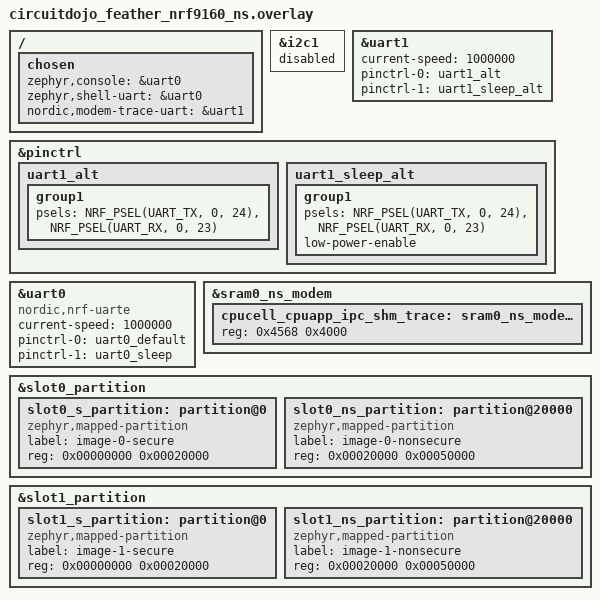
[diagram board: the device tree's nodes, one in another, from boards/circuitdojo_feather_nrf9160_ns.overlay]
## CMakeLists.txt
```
cmake_minimum_required(VERSION 3.20.0)

# Either authentication mode is selectable at build time.
set(SAMPLE_TLS verify psk)
include(${CMAKE_CURRENT_SOURCE_DIR}/../common/app.cmake)

find_package(Zephyr REQUIRED HINTS $ENV{ZEPHYR_BASE})
project(mqtt_init)

# The broker's trust anchor, included by main.c as a string literal on a
# certificate build. A broker with its own development CA is pointed at that
# file instead: -DPIGEON_MQTT_CA_FILE=<pem>.
set(PIGEON_MQTT_CA_FILE ${CMAKE_CURRENT_SOURCE_DIR}/cert/isrg-root-x2.pem
    CACHE FILEPATH "PEM trust anchor for the MQTT broker's certificate")

generate_inc_file_for_target(
  app ${PIGEON_MQTT_CA_FILE}
  ${ZEPHYR_BINARY_DIR}/include/generated/broker-ca.pem.hex
)

target_sources(app PRIVATE src/main.c src/shadow.c)

include(${CMAKE_CURRENT_SOURCE_DIR}/../common/net.cmake)
```

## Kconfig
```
config MQTT_INIT_PIGEON_ID
  string "Pigeon id this device connects to the broker as"
  default ""
  help
    The pigeon's own 64-character hex id, passed to pigeon_init() as
    pigeon_config.device_id. On this connector it is the CONNECT client id
    and username, and on a PSK build the handshake identity as well; the
    broker refuses a session whose three copies of it disagree. It is
    credential-shaped, so it belongs in the git-ignored prj.local.conf.

    The empty default fails at pigeon_mqtt_start() rather than connecting
    as nobody.

menu "Zephyr Kernel"
source "Kconfig.zephyr"
endmenu
```

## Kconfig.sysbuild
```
rsource "../Kconfig.sysbuild.signing"

# A Feather has nothing at address 0 without MCUboot. The ESP32-C6 board
# defaults to MCUboot, and this sample stages no firmware, so one image is
# enough there.
choice BOOTLOADER
	default BOOTLOADER_NONE if BOARD_ESP32C6_DEVKITC
	default BOOTLOADER_MCUBOOT if SOC_SERIES_NRF91
endchoice

source "share/sysbuild/Kconfig"
```

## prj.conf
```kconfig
# The Pigeon client library over MQTT: one persistent TLS session to the
# platform's broker, which bridges every publish onto the device routes. The
# endpoint names the broker rather than this pigeon (mqtts://<host>:8883, no
# path), and the pigeon id, token and PSK secret are device identity, so all
# of them belong in the git-ignored prj.local.conf.
CONFIG_PIGEON=y
CONFIG_PIGEON_CONNECTOR_MQTT=y
# The modem's credential store outlives a reflash and is keyed by tag, so each
# sample here owns a distinct one rather than the shared default.
CONFIG_PIGEON_MQTT_SEC_TAG=47

# Mains-powered and always on, so a minute of silence before the broker starts
# wondering is the right trade. A device that sleeps between reports wants
# this raised; the broker honours up to 30 minutes and closes after 1.5x.
CONFIG_MQTT_KEEPALIVE=60


CONFIG_LOG=y
CONFIG_LOG_DEFAULT_LEVEL=3
# Deferred, not immediate, because the log upload backend fills a ring buffer
# that is lock-free only while a single thread writes it. Deferred mode makes
# the log processing thread that sole writer.
CONFIG_LOG_MODE_DEFERRED=y
CONFIG_LOG_PROCESS_THREAD_STACK_SIZE=2048
# Lets the shadow's "log" field silence and restore logging at runtime.
CONFIG_LOG_RUNTIME_FILTERING=y

# This device's own logs, uploaded as Zephyr dictionary-encoded binary. The
# console stays human-readable; only the upload backend encodes. Decoding a
# chunk needs this build's log_dictionary.json, and a dictionary from another
# build decodes to plausible nonsense rather than erroring.
CONFIG_PIGEON_LOG_UPLOAD=y
CONFIG_PIGEON_LOG_UPLOAD_BUF_SIZE=4096
CONFIG_PIGEON_LOG_UPLOAD_BATCH_SIZE=2048

CONFIG_HEAP_MEM_POOL_SIZE=8192
CONFIG_MAIN_STACK_SIZE=8192
CONFIG_SYSTEM_WORKQUEUE_STACK_SIZE=4096
# Logging from the connection manager's event callbacks overflows the default.
CONFIG_NET_MGMT_EVENT_STACK_SIZE=2048

CONFIG_NETWORKING=y
CONFIG_NET_SOCKETS=y
CONFIG_NET_SOCKETS_SOCKOPT_TLS=y
# MQTT is a stream protocol, so this needs real TCP and at least one packet
# protocol under it, or the net stack refuses to build.
CONFIG_NET_TCP=y
CONFIG_NET_IPV4=y
CONFIG_NET_IPV6=y
CONFIG_NET_CONNECTION_MANAGER=y
CONFIG_NET_CONNECTION_MANAGER_MONITOR_STACK_SIZE=1024

# Generous rather than needed. The socket layer consults this only when the
# handshake has to block, so a cap that is exceeded abandons a session the
# broker has already accepted and surfaces as a bare timeout with no TLS
# error, which reads as a broken broker rather than a slow device.
CONFIG_NET_SOCKETS_TLS_CONNECT_TIMEOUT=45000
```

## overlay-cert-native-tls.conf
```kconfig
# Certificate mode on a board whose board conf selects TLS-PSK.
#
# Both want lists are compiled in on the mbedTLS boards, so this only picks
# which one the session uses.
CONFIG_PIGEON_MQTT_AUTH_CERT=y
```

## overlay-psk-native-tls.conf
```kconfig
# TLS-PSK on a board whose board conf selects certificate mode.
#
# Both want lists are compiled in on the mbedTLS boards, so this only picks
# which one the session uses.
CONFIG_PIGEON_MQTT_AUTH_PSK=y
# The broker's third PSK suite is AES-128-CBC; the shared fragment covers the
# other two.
CONFIG_PSA_WANT_ALG_CBC_NO_PADDING=y
```

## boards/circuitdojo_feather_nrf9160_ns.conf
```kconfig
# Beyond ../../common/boards/nrf91.conf.

# TLS-PSK: the modem holds the identity and secret in its own credential
# store, which the library writes at pigeon_init() time, and the broker
# resolves this pigeon's token server-side from the handshake identity.
CONFIG_PIGEON_MQTT_AUTH_PSK=y

# Modem trace on uart1 (see the overlay); the backend choice only applies
# once the trace subsystem itself is on.
CONFIG_NRF_MODEM_LIB_TRACE=y
CONFIG_NRF_MODEM_LIB_TRACE_BACKEND_UART=y
CONFIG_UART_1_ASYNC=y
CONFIG_UART_1_INTERRUPT_DRIVEN=n
```

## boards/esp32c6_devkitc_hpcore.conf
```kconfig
# Beyond ../../common/boards/esp32c6.conf.

# Certificate authentication: the shape every off-the-shelf MQTT client also
# speaks. The broker serves a Let's Encrypt chain, this build verifies it
# against cert/isrg-root-x2.pem, and the CONNECT password is
# CONFIG_PIGEON_TOKEN.
CONFIG_PIGEON_MQTT_AUTH_CERT=y
```

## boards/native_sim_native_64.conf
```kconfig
# Beyond ../../common/boards/native_sim.conf.

# TLS-PSK: the mode with nothing to provision, since the library registers the
# identity and secret itself from pigeon_init()'s config.
CONFIG_PIGEON_MQTT_AUTH_PSK=y
# The broker's third PSK suite is AES-128-CBC; the shared fragment covers the
# other two.
CONFIG_PSA_WANT_ALG_CBC_NO_PADDING=y
```

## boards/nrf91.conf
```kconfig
# Both nRF91 Feathers, on top of ../../common/boards/nrf91.conf.

# TLS-PSK: the modem holds the identity and secret in its own credential
# store, which the library writes at pigeon_init() time, and the broker
# resolves this pigeon's token server-side from the handshake identity.
CONFIG_PIGEON_MQTT_AUTH_PSK=y

# Modem trace on uart1 (see the overlay); the backend choice only applies
# once the trace subsystem itself is on.
CONFIG_NRF_MODEM_LIB_TRACE=y
CONFIG_NRF_MODEM_LIB_TRACE_BACKEND_UART=y
CONFIG_UART_1_ASYNC=y
CONFIG_UART_1_INTERRUPT_DRIVEN=n
```

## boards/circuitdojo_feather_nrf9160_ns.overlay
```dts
/* i2c1 shares its peripheral instance with the trace UART below. */
&i2c1 {
    status = "disabled";
};

/* Modem trace UART. */
&uart1 {
    status = "okay";
    current-speed = <1000000>;
    pinctrl-0 = <&uart1_alt>;
    pinctrl-1 = <&uart1_sleep_alt>;
    pinctrl-names = "default", "sleep";
};

&pinctrl {
    uart1_alt: uart1_alt {
        group1 {
            psels = <NRF_PSEL(UART_TX, 0, 24)>,
                <NRF_PSEL(UART_RX, 0, 23)>;
        };
    };

    uart1_sleep_alt: uart1_sleep_alt {
        group1 {
            psels = <NRF_PSEL(UART_TX, 0, 24)>,
                <NRF_PSEL(UART_RX, 0, 23)>;
            low-power-enable;
        };
    };
};

&uart0 {
  status = "okay";
  compatible = "nordic,nrf-uarte";
  current-speed = <1000000>;
  pinctrl-0 = <&uart0_default>;
  pinctrl-1 = <&uart0_sleep>;
  pinctrl-names = "default", "sleep";
};

/* The modem trace buffer fits in the slack the stock partition file leaves
 * inside the modem shared-memory region, so nothing else has to move.
 * Nordic's own modem-trace snippet sizes it for a different SRAM total and
 * overflows this board. */
&sram0_ns_modem {
  cpucell_cpuapp_ipc_shm_trace: sram0_ns_modem@4568 {
    reg = <0x4568 0x4000>;
  };
};

/* The stock 256/192 KiB secure/non-secure split leaves TF-M most of its
 * share unused while this application overflows its own. The slot total is
 * unchanged, so MCUboot's overlay needs nothing. */
/delete-node/ &slot0_s_partition;
/delete-node/ &slot0_ns_partition;

&slot0_partition {
  slot0_s_partition: partition@0 {
    compatible = "zephyr,mapped-partition";
    label = "image-0-secure";
    reg = <0x00000000 0x00020000>;
  };

  slot0_ns_partition: partition@20000 {
    compatible = "zephyr,mapped-partition";
    label = "image-0-nonsecure";
    reg = <0x00020000 0x00050000>;
  };
};

/delete-node/ &slot1_s_partition;
/delete-node/ &slot1_ns_partition;

&slot1_partition {
  slot1_s_partition: partition@0 {
    compatible = "zephyr,mapped-partition";
    label = "image-1-secure";
    reg = <0x00000000 0x00020000>;
  };

  slot1_ns_partition: partition@20000 {
    compatible = "zephyr,mapped-partition";
    label = "image-1-nonsecure";
    reg = <0x00020000 0x00050000>;
  };
};

/ {
  chosen {
    zephyr,console = &uart0;
    zephyr,shell-uart = &uart0;
    nordic,modem-trace-uart = &uart1;
  };
};
```

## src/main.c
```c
#include <pigeon.h>
#include <zephyr/kernel.h>
#include <zephyr/logging/log.h>

#include "net_connect.h"
#include "shadow.h"

LOG_MODULE_REGISTER(main);

#if defined(CONFIG_PIGEON_MQTT_AUTH_CERT)
/* The broker's trust anchor, terminated because mbedTLS parses PEM as a string. */
static const char ca_cert[] = {
#include "broker-ca.pem.hex"
    0x00
};

BUILD_ASSERT(sizeof(ca_cert) < KB(4), "the modem's credential store caps a certificate at 4 KiB");
#endif

/* A Kconfig string is always defined, so "" is its only way of saying "not
 * supplied"; to pigeon_init() a non-NULL empty string is a zero-length
 * credential that fails every handshake. */
#define PSK_CONF_OR_NULL(s) ((s)[0] ? (s) : NULL)

/* A PSK build has nothing to install: pigeon_init() registers the identity and
 * secret itself. */
static int install_broker_ca(void) {
#if defined(CONFIG_PIGEON_MQTT_AUTH_CERT)
  return net_install_ca(CONFIG_PIGEON_MQTT_SEC_TAG, ca_cert, sizeof(ca_cert));
#else
  return 0;
#endif
}

int main(void) {
  /* device_id is the CONNECT client id and username, and on a PSK session the
   * handshake identity too; the broker refuses a session whose three copies
   * of it disagree, so it is a credential and lives in prj.local.conf. */
  struct pigeon_config config = {
      .device_id = CONFIG_MQTT_INIT_PIGEON_ID,
      .connector =
          {
              .type = PIGEON_CONNECTOR_MQTT,
              .mqtt =
                  {
#if defined(CONFIG_PIGEON_MQTT_AUTH_PSK)
                      .tls_psk_identity = PSK_CONF_OR_NULL(CONFIG_MQTT_INIT_PIGEON_ID),
                      .tls_psk_secret = PSK_CONF_OR_NULL(CONFIG_PIGEON_MQTT_TLS_PSK_SECRET),
#endif
                  },
          },
  };

  int err = net_prepare();

  if (!err) {
    err = install_broker_ca();
  }

  if (err) {
    LOG_ERR("Credential setup failed: %d", err);
    return err;
  }

  err = pigeon_init(&config);
  if (err) {
    return err;
  }

  err = net_connect();
  if (err) {
    return err;
  }

  /* The session is the transport on this connector, so there is no polling
   * to fall back to when it fails. */
  err = pigeon_mqtt_start(shadow_event_cb);
  if (err) {
    LOG_ERR("pigeon_mqtt_start() failed: %d", err);
    net_disconnect();
    return err;
  }

  shadow_loop();

  pigeon_mqtt_stop();

  return net_disconnect();
}
```

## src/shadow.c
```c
/** @headerfile shadow.h */
#include "shadow.h"

#include <pigeon.h>
#include <string.h>
#include <zephyr/data/json.h>
#include <zephyr/kernel.h>
#include <zephyr/logging/log.h>
#include <zephyr/logging/log_ctrl.h>
#include <zephyr/sys/printk.h>

#include "net_connect.h"

LOG_MODULE_REGISTER(shadow);

/* Signalled from the library's MQTT worker thread so shadow_loop() applies a
 * pushed target without waiting out its telemetry_interval. */
K_SEM_DEFINE(shadow_wakeup, 0, 1);

void shadow_event_cb(enum pigeon_event ev, const struct pigeon_shadow_doc *shadow) {
  /* A push is a wakeup, not a data path: shadow_sync() reads the same
   * retained value back, which keeps one code path for both cases. */
  ARG_UNUSED(shadow);

  switch (ev) {
    case PIGEON_EVENT_CONNECTED:
      /* A fresh session seeds its retained target immediately, and the
       * platform may have moved on while this device was away. */
    case PIGEON_EVENT_SHADOW_UPDATE:
      k_sem_give(&shadow_wakeup);
      break;
    case PIGEON_EVENT_DISCONNECTED:
      /* The reconnect is the library's; the periodic tick is the safety net. */
      break;
  }
}

/* target_config is opaque JSON to the library; this application decides what
 * its keys mean. */
struct app_shadow_config {
  bool log;
  int telemetry_interval;
  bool reboot;
};

static const struct json_obj_descr app_shadow_config_descr[] = {
    JSON_OBJ_DESCR_PRIM(struct app_shadow_config, log, JSON_TOK_TRUE),
    JSON_OBJ_DESCR_PRIM(struct app_shadow_config, telemetry_interval, JSON_TOK_NUMBER),
    JSON_OBJ_DESCR_PRIM(struct app_shadow_config, reboot, JSON_TOK_TRUE),
};

/* Defaults applied before the first sync of a boot. Nothing persists across
 * reboots, so every boot re-applies the platform's target from here. */
static struct app_shadow_config current_config = {
    .log = false,
    .telemetry_interval = 60,
    .reboot = false,
};

/* One call covers every module, so the shadow's "log" field really silences
 * and restores output. */
static void set_all_log_levels(uint32_t level) {
  uint32_t module_count = log_src_cnt_get(Z_LOG_LOCAL_DOMAIN_ID);

  for (uint32_t i = 0; i < module_count; i++) {
    log_filter_set(NULL, Z_LOG_LOCAL_DOMAIN_ID, (int16_t)i, level);
  }
}

/* Both keys ride one publish to the telemetry topic. poll_count restarting at
 * 1 doubles as a reboot indicator on the dashboard. */
static void report_telemetry(void) {
  static unsigned int poll_count;
  char buf[21];

  snprintk(buf, sizeof(buf), "%lld", (long long)(k_uptime_get() / 1000));

  int err = pigeon_telemetry_set("uptime_s", buf);

  snprintk(buf, sizeof(buf), "%u", ++poll_count);

  if (!err) {
    err = pigeon_telemetry_set("poll_count", buf);
  }

  if (!err) {
    err = pigeon_telemetry_flush();
  }

  if (err) {
    LOG_WRN("Telemetry report failed: %d", err);
  }
}

int shadow_sync(void) {
  struct pigeon_shadow_doc doc;
  /* Serves whatever the broker last pushed rather than fetching anything. */
  int err = pigeon_shadow_get(&doc);

  if (err) {
    LOG_ERR("No target shadow available: %d", err);
    return err;
  }

  LOG_INF(
      "Shadow: target_version=%d current_version=%d updated_at=%lld", doc.target_version,
      doc.current_version, doc.updated_at
  );

  report_telemetry();

  if (doc.target_version == doc.current_version) {
    LOG_INF("Shadow already converged at version %d; nothing to apply", doc.current_version);
    return 0;
  }

  /* json_obj_parse() edits its input, and target_config only lives until the
   * next push. */
  char config_buf[CONFIG_PIGEON_SHADOW_CONFIG_MAX];

  strncpy(config_buf, doc.target_config, sizeof(config_buf) - 1);
  config_buf[sizeof(config_buf) - 1] = '\0';

  /* Keys absent from a partial update keep their current value. reboot is a
   * one-shot command and always starts false. */
  struct app_shadow_config target = current_config;

  target.reboot = false;

  int64_t decoded = json_obj_parse(
      config_buf, strlen(config_buf), app_shadow_config_descr, ARRAY_SIZE(app_shadow_config_descr),
      &target
  );

  if (decoded < 0) {
    LOG_ERR("Failed to parse shadow target_config: %lld", decoded);
    return (int)decoded;
  }

  if (target.log != current_config.log) {
    LOG_INF(
        "Shadow v%d: log %s -> %s", doc.target_version, current_config.log ? "true" : "false",
        target.log ? "true" : "false"
    );
    set_all_log_levels(target.log ? CONFIG_LOG_DEFAULT_LEVEL : LOG_LEVEL_NONE);
  }

  if (target.telemetry_interval != current_config.telemetry_interval) {
    LOG_INF(
        "Shadow v%d: telemetry_interval %d -> %d", doc.target_version,
        current_config.telemetry_interval, target.telemetry_interval
    );
  }

  current_config.log = target.log;
  current_config.telemetry_interval = target.telemetry_interval;

  LOG_INF(
      "Applied shadow v%d: log=%s telemetry_interval=%d", doc.target_version,
      current_config.log ? "true" : "false", current_config.telemetry_interval
  );

  /* current_version is whatever this device reports, so the report goes out
   * even if a newer target is already pending by the time it lands. */
  char report_buf[128];
  int encode_err = json_obj_encode_buf(
      app_shadow_config_descr, ARRAY_SIZE(app_shadow_config_descr), &current_config, report_buf,
      sizeof(report_buf)
  );

  if (encode_err) {
    LOG_ERR("Failed to encode current_config for shadow report: %d", encode_err);
  } else {
    int report_err = pigeon_shadow_report(doc.target_version, report_buf);

    if (report_err) {
      LOG_WRN("Shadow report-back failed: %d", report_err);
    } else {
      LOG_INF("Reported current_config back to platform at v%d", doc.target_version);
    }
  }

  /* reboot is a command rather than a persistent field, so it stays out of
   * current_config: kept there it would never look changed again and the
   * device would reboot on every pass. The session is ended with a real
   * DISCONNECT first, which is what stops the broker publishing this
   * session's will. */
  if (target.reboot) {
    LOG_WRN("Shadow v%d requested reboot; disconnecting and rebooting now", doc.target_version);
    pigeon_mqtt_stop();
    net_disconnect();
    pigeon_reboot();
  }

  return 0;
}

void shadow_loop(void) {
  while (1) {
    shadow_sync();

    LOG_INF(
        "Next pass in <=%d s (or sooner on a pushed shadow)", current_config.telemetry_interval
    );
    k_sem_take(&shadow_wakeup, K_SECONDS(current_config.telemetry_interval));
  }
}
```

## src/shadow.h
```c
/** @file shadow.h
 *  @brief Applies the pigeon's target shadow, which on this connector the
 *  broker pushes rather than the device polling for it.
 */
#ifndef SHADOW_H
#define SHADOW_H

#include <pigeon.h>

/** pigeon_mqtt_start() event callback: a connect or a pushed shadow wakes
 *  shadow_loop() to apply it now instead of at the next tick. Runs on the
 *  library's MQTT worker thread, so it only signals. */
void shadow_event_cb(enum pigeon_event ev, const struct pigeon_shadow_doc *shadow);

/** Reads the pigeon's target shadow, applies target_config if the platform
 *  has moved past what this boot applied, reports the result back and reports
 *  telemetry.
 *  @return 0 whether or not an update was applied, negative on transport or
 *  parse failure. */
int shadow_sync(void);

/** Repeatedly shadow_sync(), waiting the shadow's own telemetry_interval
 *  between passes or less when the broker pushes a new target. Does not
 *  return under normal operation. */
void shadow_loop(void);

#endif
```
